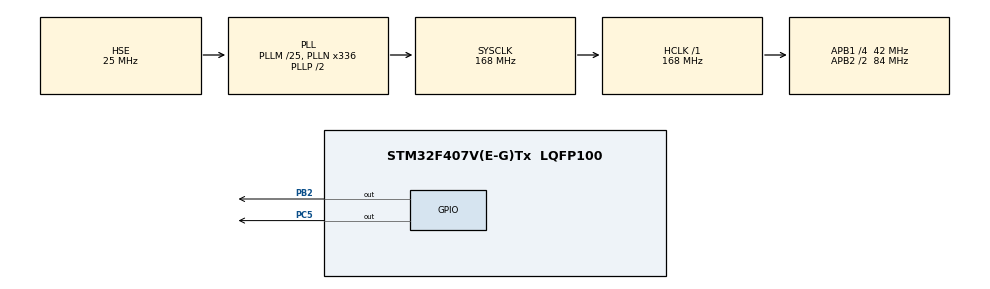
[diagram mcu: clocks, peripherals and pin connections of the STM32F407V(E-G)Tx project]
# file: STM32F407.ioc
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Mcu.Family=STM32F4
Mcu.Name=STM32F407V(E-G)Tx
Mcu.Package=LQFP100
NVIC.PriorityGroup=NVIC_PRIORITYGROUP_4
PA13.Mode=Serial_Wire
PA13.Signal=SYS_JTMS-SWDIO
PA14.Mode=Serial_Wire
PA14.Signal=SYS_JTCK-SWCLK
PB2.Signal=GPIO_Output
PC5.Signal=GPIO_Output
PH0-OSC_IN.Mode=HSE-External-Oscillator
PH0-OSC_IN.Signal=RCC_OSC_IN
PH1-OSC_OUT.Mode=HSE-External-Oscillator
PH1-OSC_OUT.Signal=RCC_OSC_OUT
ProjectManager.HeapSize=0x200
ProjectManager.StackSize=0x1000
ProjectManager.TargetToolchain=MDK-ARM V5.32
RCC.48MHZClocksFreq_Value=84000000
RCC.AHBFreq_Value=168000000
RCC.APB1CLKDivider=RCC_HCLK_DIV4
RCC.APB1Freq_Value=42000000
RCC.APB1TimFreq_Value=84000000
RCC.APB2CLKDivider=RCC_HCLK_DIV2
RCC.APB2Freq_Value=84000000
RCC.APB2TimFreq_Value=168000000
RCC.CortexFreq_Value=168000000
RCC.HCLKFreq_Value=168000000
RCC.HSE_VALUE=25000000
RCC.HSI_VALUE=16000000
RCC.LSE_VALUE=32768
RCC.PLLM=25
RCC.PLLN=336
RCC.PLLSourceVirtual=RCC_PLLSOURCE_HSE
RCC.SYSCLKFreq_VALUE=168000000
RCC.SYSCLKSource=RCC_SYSCLKSOURCE_PLLCLK
RCC.VCOOutputFreq_Value=336000000
board=custom

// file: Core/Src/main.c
/* USER CODE BEGIN Header */
/***********************************************************************************************************************************
 ** 【代码编写】  魔女开发板团队
 ** 【淘    宝】  魔女开发板       https://demoboard.taobao.com
 ***********************************************************************************************************************************
 ** 【实验名称】  STM32F407 GPIO 输出 —— LED 点亮实验
 **
 ** 【适用平台】  STM32F407 + keil5 + HAL库
 **
 ** 【 CubeMX 】  1- 开启外部高速晶振 HSE，系统时钟配置为 168MHz；
 **               2- 将 PB2、PC5 引脚配置为 GPIO 推挽输出模式；
 **               3- 引脚默认电平可根据需求配置，本实验代码中手动设置；
 **               4- 无需开启其他外设，仅配置基础 GPIO 即可；
 **
 ** 【功能说明】  本工程实现最基础的 GPIO 输出控制：
 **               1- PB2 引脚控制蓝色 LED，低电平点亮、高电平熄灭；
 **               2- PC5 引脚控制绿色 LED，低电平点亮、高电平熄灭；
 **               3- 上电后直接点亮双灯，演示 GPIO 输出控制；
 **               4- 代码极简，适合新手入门，理解 STM32 引脚操作；
 **
 ** 【代码使用】  1- 编译下载后，蓝灯、绿灯立即常亮；
 **               2- 修改代码中 GPIO_PIN_SET / RESET 可切换亮灭状态；
 **               3- 无循环、无延时，纯 IO 输出控制，最基础入门实验；
 **
 ** 【划 重 点】  1- 本开发板 LED 为**低电平点亮**，高电平熄灭；
 **               2- GPIO 操作函数：HAL_GPIO_WritePin(端口, 引脚, 电平);
 **               3- CubeMX 生成代码后，用户逻辑必须写在 USER CODE 区间内；
 **               4- 新手入门第一个实验，理解 IO 口输出原理；
 **
 *******************************************************************************/
/* USER CODE END Header */
#include "main.h"
#include "gpio.h"

void SystemClock_Config(void);

int main(void)
{
    /* USER CODE BEGIN 1 */

    /* 说明：
     * 1. 不要删除CubeMX生成的注释行（形如 USER CODE BEGIN/END），这些注释用于代码重新生成时的定位
     * 2. 所有用户自定义代码必须写在对应的BEGIN与END注释行之间，否则重新生成时会被覆盖
     * 3. 主要初始化函数说明：
     *    - HAL_Init()            初始化HAL库，配置中断优先级、系统时基等
     *    - SystemClock_Config()  配置系统时钟
     *    - MX_GPIO_Init()        初始化GPIO引脚（仅包含推挽输出、中断触发等配置）
     *    - 外设功能引脚（如UART、SPI等）的初始化在各自的功能文件中
     */

    /* USER CODE END 1 */

    /* MCU Configuration--------------------------------------------------------*/

    /* Reset of all peripherals, Initializes the Flash interface and the Systick. */
    HAL_Init();

    /* Configure the system clock */
    SystemClock_Config();

    /* Initialize all configured peripherals */
    MX_GPIO_Init();
    /* USER CODE BEGIN 2 */

    /** 所有用户代码，必须写在配对的BEGIN与END注释行之间, 否则CubeMX重新生成代码时，会被干掉**/

    HAL_GPIO_WritePin(GPIOB, GPIO_PIN_2, GPIO_PIN_RESET);       // PB2置低电平，蓝灯亮
    HAL_GPIO_WritePin(GPIOC, GPIO_PIN_5, GPIO_PIN_RESET);       // PC5置低电平，绿灯亮

    // HAL_GPIO_WritePin(GPIOB, GPIO_PIN_2, GPIO_PIN_SET);      // PB2置高电平，蓝灯灭
    // HAL_GPIO_WritePin(GPIOC, GPIO_PIN_5, GPIO_PIN_SET);      // PC5置高电平，绿灯灭

    /* USER CODE END 2 */

    /* Infinite loop */
    while (1)
    {

    }
}

void SystemClock_Config(void)
{
    RCC_OscInitTypeDef RCC_OscInitStruct = {0};
    RCC_ClkInitTypeDef RCC_ClkInitStruct = {0};

    /** Configure the main internal regulator output voltage
    */
    __HAL_RCC_PWR_CLK_ENABLE();
    __HAL_PWR_VOLTAGESCALING_CONFIG(PWR_REGULATOR_VOLTAGE_SCALE1);

    /** Initializes the RCC Oscillators according to the specified parameters
    * in the RCC_OscInitTypeDef structure.
    */
    RCC_OscInitStruct.OscillatorType = RCC_OSCILLATORTYPE_HSE;
    RCC_OscInitStruct.HSEState = RCC_HSE_ON;
    RCC_OscInitStruct.PLL.PLLState = RCC_PLL_ON;
    RCC_OscInitStruct.PLL.PLLSource = RCC_PLLSOURCE_HSE;
    RCC_OscInitStruct.PLL.PLLM = 25;
    RCC_OscInitStruct.PLL.PLLN = 336;
    RCC_OscInitStruct.PLL.PLLP = RCC_PLLP_DIV2;
    RCC_OscInitStruct.PLL.PLLQ = 4;
    if (HAL_RCC_OscConfig(&RCC_OscInitStruct) != HAL_OK)
    {
        Error_Handler();
    }

    /** Initializes the CPU, AHB and APB buses clocks
    */
    RCC_ClkInitStruct.ClockType = RCC_CLOCKTYPE_HCLK | RCC_CLOCKTYPE_SYSCLK
                                  | RCC_CLOCKTYPE_PCLK1 | RCC_CLOCKTYPE_PCLK2;
    RCC_ClkInitStruct.SYSCLKSource = RCC_SYSCLKSOURCE_PLLCLK;
    RCC_ClkInitStruct.AHBCLKDivider = RCC_SYSCLK_DIV1;
    RCC_ClkInitStruct.APB1CLKDivider = RCC_HCLK_DIV4;
    RCC_ClkInitStruct.APB2CLKDivider = RCC_HCLK_DIV2;

    if (HAL_RCC_ClockConfig(&RCC_ClkInitStruct, FLASH_LATENCY_5) != HAL_OK)
    {
        Error_Handler();
    }
}

void Error_Handler(void)
{
    __disable_irq();
    while (1)
    {
    }
}
